# UM8 register map
Vendor: Redshift Labs Pty Ltd; Series: IMU; File version: 0.1
UM8 Board Peripheral Description
Address unit: 32 bits
Registers are 32-bit, read-only, reset 0x0 unless marked. A register's access mark holds for its fields unless they carry their own. Offsets are from the block's base; lines under a group give offsets from that group; [hi:lo] are bit positions; {n}, {i} and the like mark numbered series; 'fields as' and 'values as' point back to an identical list; <NAME> marks a mode.

## Memory map
0x00000000 MAIN_REGISTER_MAP size 0x500 — Main register map for the UM8 board
0x00000000 HIDDEN_REGISTER_MAP size 0x500 — Hidden register map for the UM8 board

## MAIN_REGISTER_MAP — Main register map for the UM8 board
Base 0x00000000
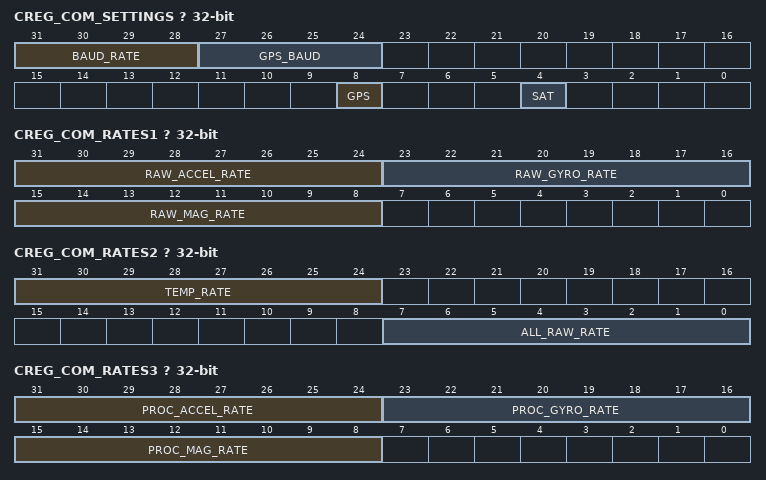
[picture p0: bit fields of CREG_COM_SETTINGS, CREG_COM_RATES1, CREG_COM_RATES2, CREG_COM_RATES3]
? CREG_COM_SETTINGS rw — The CREG_COM_SETTINGS register is used to set the boards serial port baud rate and to enable (disable) the automatic transmission of sensor data and estimated states (telemetry).
  [31:28] BAUD_RATE — Sets the baud rate of the boards main serial port:
    0=Baud rate: 9600; 1=Baud rate: 14400; 2=Baud rate: 19200; 3=Baud rate: 38400; 4=Baud rate: 57600; 5=Baud rate: 115200; 6=Baud rate: 128000; 7=Baud rate: 153600; 8=Baud rate: 230400; 9=Baud rate: 256000; 10=Baud rate: 460800; 11=Baud rate: 921600
  [27:24] GPS_BAUD — Sets the baud rate of the UM8 auxiliary serial port:
    0=Baud rate: 9600; 1=Baud rate: 14400; 2=Baud rate: 19200; 3=Baud rate: 38400; 4=Baud rate: 57600; 5=Baud rate: 115200
  [8] GPS — If set, this bit causes GPS data to be transmitted automatically whenever new GPS data is received. GPS data is stored in registers 125 to 130. These registers will be transmitted in a batch packet of length 6 starting at address 125.
    1=GPS_DATA_ON (GPS data will be transmitted automatically whenever new GPS data is received.); 0=GPS_DATA_OFF (GPS data will *not* be transmitted automatically whenever new GPS data is received.)
  [4] SAT — If set, this bit causes satellite details to be transmitted whenever they are provided by the GPS. Satellite information is stored in registers 131 to 136. These registers will be transmitted in a batch packet of length 6 beginning at address 131.
    1=SAT_DETAILS_ON (Satellite details will be transmitted whenever they are provided by the GPS.); 0=SAT_DETAILS_OFF (Satellite details will not be transmitted whenever they are provided by the GPS.)
? CREG_COM_RATES1 rw — The CREG_COM_RATES1 register sets desired telemetry transmission rates in Hz for raw accelerometer, gyro, and magnetometer data. If the specified rate is 0, then no data is transmitted.
  [31:24] RAW_ACCEL_RATE — Specifies the desired raw accelerometer data broadcast rate in Hz. The data is stored as an unsigned 8-bit integer, yielding a maximum rate of 255 Hz.
  [23:16] RAW_GYRO_RATE — Specifies the desired raw gyro data broadcast rate in Hz. The data is stored as an unsigned 8-bit integer, yielding a maximum rate of 255 Hz.
  [15:8] RAW_MAG_RATE — Specifies the desired raw magnetometer data broadcast rate in Hz. The data is stored as an unsigned 8-bit integer, yielding a maximum rate of 255 Hz.
? CREG_COM_RATES2 rw — The CREG_COM_RATES2 register sets desired telemetry transmission rates for all raw data and temperature. If the specified rate is 0, then no data is transmitted.
  [31:24] TEMP_RATE — Specifies the desired broadcast rate for temperature data. The data is stored as an unsigned 8-bit integer, yielding a maximum rate of 255 Hz.
  [7:0] ALL_RAW_RATE — Specifies the desired broadcast rate for all raw sensor data. If set, this overrides the broadcast rate setting for individual raw data broadcast rates. The data is stored as an unsigned 8-bit integer, yielding a maximum rate of 255 Hz.
? CREG_COM_RATES3 rw — The CREG_COM_RATES3 register sets desired telemetry transmission rates for processed sensor data. If the specified rate is 0, then no data is transmitted.
  [31:24] PROC_ACCEL_RATE — Specifies the desired broadcast rate for processed accelerometer data. The data is stored as an unsigned 8-bit integer, yielding a maximum rate of 255 Hz.
  [23:16] PROC_GYRO_RATE — Specifies the desired broadcast rate for processed rate gyro data. The data is stored as an unsigned 8-bit integer, yielding a maximum rate of 255 Hz.
  [15:8] PROC_MAG_RATE — Specifies the desired broadcast rate for processed magnetometer data. The data is stored as an unsigned 8-bit integer, yielding a maximum rate of 255 Hz.
? CREG_COM_RATES4 rw — The CREG_COM_RATES4 register defines the desired telemetry transmission rates for all processed data. If the specified rate is 0, then no data is transmitted.
  [7:0] ALL_PROC_RATE — Specifies the desired broadcast rate for raw all processed data. If set, this overrides the broadcast rate setting for individual processed data broadcast rates. The data is stored as an unsigned 8-bit integer, yielding a maximum rate of 255 Hz.
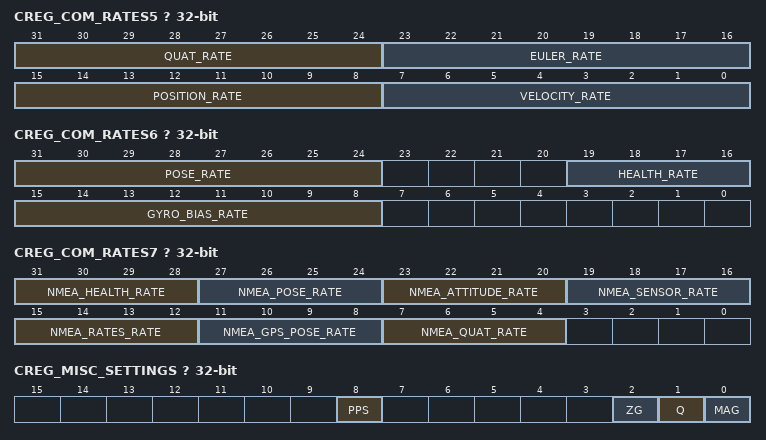
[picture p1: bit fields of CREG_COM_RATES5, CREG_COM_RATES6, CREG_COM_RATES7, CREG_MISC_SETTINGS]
? CREG_COM_RATES5 rw — The CREG_COM_RATES5 register sets desired telemetry transmission rates for quaternions, Euler Angles, position, and velocity estimates. If the specified rate is 0, then no data is transmitted.
  [31:24] QUAT_RATE — Specifies the desired broadcast rate for quaternion data. The data is stored as an unsigned 8-bit integer, yielding a maximum rate of 255 Hz.
  [23:16] EULER_RATE — Specifies the desired broadcast rate for Euler Angle data. The data is stored as an unsigned 8-bit integer, yielding a maximum rate of 255 Hz.
  [15:8] POSITION_RATE — Specifies the desired broadcast rate position. The data is stored as an unsigned 8-bit integer, yielding a maximum rate of 255 Hz.
  [7:0] VELOCITY_RATE — Specifies the desired broadcast rate for velocity. The data is stored as an unsigned 8-bit integer, yielding a maximum rate of 255 Hz.
? CREG_COM_RATES6 rw — The CREG_COM_RATES6 register sets desired telemetry transmission rates for pose (Euler/position packet), health, and gyro bias estimates for the gyro 1 and gyro 2. If the specified rate is 0, then no data is transmitted.
  [31:24] POSE_RATE — Specifies the desired broadcast rate for pose (Euler Angle and position) data. The data is stored as an unsigned 8-bit integer, yielding a maximum rate of 255 Hz.
  [19:16] HEALTH_RATE — Specifies the desired broadcast rate for the sensor health packet.
    0=Packet frequency: OFF; 1=0_125 (Packet frequency: 0.125 Hz); 2=0_25 (Packet frequency: 0.25 Hz); 3=0_5 (Packet frequency: 0.5 Hz); 4=Packet frequency: 1 Hz; 5=Packet frequency: 2 Hz; 6=Packet frequency: 4 Hz
  [15:8] GYRO_BIAS_RATE — Specifies the desired broadcast rate for gyro bias estimates. The data is stored as an unsigned 8-bit integer, yielding a maximum rate of 255 Hz.
? CREG_COM_RATES7 rw — The CREG_COM_RATES7 register sets desired telemetry transmission rates in Hz for NMEA packets.
  [all] fields
    0=Packet frequency: OFF; 1=Packet frequency: 1 Hz; 2=Packet frequency: 2 Hz; 3=Packet frequency: 4 Hz; 4=Packet frequency: 5 Hz; 5=Packet frequency: 10 Hz; 6=Packet frequency: 15 Hz; 7=Packet frequency: 20 Hz; 8=Packet frequency: 30 Hz; 9=Packet frequency: 40 Hz; 10=Packet frequency: 50 Hz; 11=Packet frequency: 60 Hz; 12=Packet frequency: 70 Hz; 13=Packet frequency: 80 Hz; 14=Packet frequency: 90 Hz; 15=Packet frequency: 100 Hz
  [31:28] NMEA_HEALTH_RATE — Specifies the desired broadcast rate for Redshift Labs Pty Ltd NMEA-style health packet.
  [27:24] NMEA_POSE_RATE — Specifies the desired broadcast rate for Redshift Labs Pty Ltd NMEA-style pose (Euler Angle/position) packet.
  [23:20] NMEA_ATTITUDE_RATE — Specifies the desired broadcast rate for Redshift Labs Pty Ltd NMEA-style attitude packet.
  [19:16] NMEA_SENSOR_RATE — Specifies the desired broadcast rate for Redshift Labs Pty Ltd NMEA-style sensor data packet.
  [15:12] NMEA_RATES_RATE — Specifies the desired broadcast rate for Redshift Labs Pty Ltd NMEA-style rate data packet.
  [11:8] NMEA_GPS_POSE_RATE — Specifies the desired broadcast rate for Redshift Labs Pty Ltd NMEA-style GPS pose packet.
  [7:4] NMEA_QUAT_RATE — Specifies the desired broadcast rate for Redshift Labs Pty Ltd NMEA-style quaternion packet.
? CREG_MISC_SETTINGS rw — This register contains miscellaneous filter and sensor control options.
  [8] PPS — If set, this bit causes the TX2 pin on the IO Expansion header to be used as the PPS input from an external GPS module. PPS pulses will then be used to synchronize the system clock to UTC time of day.
    0=PPS_OFF (TX2 not used as PPS input from GPS); 1=PPS_ON (TX2 used as PPS input from GPS)
  [2] ZG — If set, this bit causes the device to attempt to measure the rate gyro bias on startup. The sensor must be stationary on startup for this feature to work properly.
    0=ZG_OFF (NOT measure rate gyro bias on startup); 1=ZG_ON (Measure rate gyro bias on startup)
  [1] Q — If this bit is set, the sensor will run in quaternion mode instead of Euler Angle mode.
    0=EULER_MODE (The sensor will run in Euler Angle mode); 1=QUATERNION_MODE (The sensor will run in quaternion mode)
  [0] MAG — If set, the magnetometer will be used in state updates.
    0=MAG_NOT_IN_STATE (NOT use magnetometer in state update); 1=MAG_IN_STATE (Use magnetometer in state update)
? CREG_HOME_NORTH rw — This register sets the north home latitude in degrees, used to convert GPS coordinates to position in meters from home.
  [31:0] SET_HOME_NORTH — North Position (32-bit IEEE Floating Point Value)
? CREG_HOME_EAST rw — This register sets the east home longitude in degrees, used to convert GPS coordinates to position in meters from home.
  [31:0] SET_HOME_EAST — East Position (32-bit IEEE Floating Point Value)
? CREG_HOME_UP rw — This register sets the home altitude in meters. Used to convert GPS coordinates to position in meters from home.
  [31:0] SET_HOME_UP — Altitude Position (32-bit IEEE Floating Point Value)
? CREG_GYRO_TRIM_X rw — This register sets the x-axis rate gyro trim, which is used to add additional bias compensation for the rate gyros during calls to the ZERO_GYRO_BIAS command.
  [31:0] GYRO_TRIM_X — 32-bit IEEE Floating Point Value
? CREG_GYRO_TRIM_Y rw — This register sets the y-axis rate gyro trim, which is used to add additional bias compensation for the rate gyros during calls to the ZERO_GYRO_BIAS command.
  [31:0] GYRO_TRIM_Y — 32-bit IEEE Floating Point Value
? CREG_GYRO_TRIM_Z rw — This register sets the z-axis rate gyro trim, which is used to add additional bias compensation for the rate gyros during calls to the ZERO_GYRO_BIAS command.
  [31:0] GYRO_TRIM_Z — 32-bit IEEE Floating Point Value
? CREG_MAG_CAL{i}_1 rw (i=1..3) — Row {i}, Column 1 of magnetometer calibration matrix.
  [31:0] MAG_CAL{i}_1 — 32-bit IEEE Floating Point Value
? CREG_MAG_CAL{i}_2 rw (i=1..3) — Row {i}, Column 2 of magnetometer calibration matrix.
  [31:0] MAG_CAL{i}_2 — 32-bit IEEE Floating Point Value
? CREG_MAG_CAL{i}_3 rw (i=1..3) — Row {i}, Column 3 of magnetometer calibration matrix.
  [31:0] MAG_CAL{i}_3 — 32-bit IEEE Floating Point Value
? CREG_MAG_BIAS_X rw — This register stores a bias term for the magnetometer x-axis for hard-iron calibration. This term can be computed by performing magnetometer calibration with the Redshift labs Serial Interface.
  [31:0] MAG_BIAS_X — 32-bit IEEE Floating Point Value
? CREG_MAG_BIAS_Y rw — This register stores a bias term for the magnetometer y-axis for hard-iron calibration. This term can be computed by performing magnetometer calibration with the Redshift labs Serial Interface.
  [31:0] MAG_BIAS_Y — 32-bit IEEE Floating Point Value
? CREG_MAG_BIAS_Z rw — This register stores a bias term for the magnetometer z-axis for hard-iron calibration. This term can be computed by performing magnetometer calibration with the Redshift labs Serial Interface.
  [31:0] MAG_BIAS_Z — 32-bit IEEE Floating Point Value
? CREG_ACCEL_CAL{i}_1 rw (i=1..3) — Row {i}, Column 1 of accelerometer calibration matrix.
  [31:0] ACCEL_CAL{i}_1 — 32-bit IEEE Floating Point Value
? CREG_ACCEL_CAL{i}_2 rw (i=1..3) — Row {i}, Column 2 of accelerometer calibration matrix.
  [31:0] ACCEL_CAL{i}_2 — 32-bit IEEE Floating Point Value
? CREG_ACCEL_CAL{i}_3 rw (i=1..3) — Row {i}, Column 3 of accelerometer calibration matrix.
  [31:0] ACCEL_CAL{i}_3 — 32-bit IEEE Floating Point Value
? CREG_ACCEL_BIAS_X rw — This register stores a bias term for the accelerometer x-axis for bias calibration. This term can be computed by performing calibrate accelerometers command within the Redshift labs Serial Interface.
  [31:0] ACCEL_BIAS_X — 32-bit IEEE Floating Point Value
? CREG_ACCEL_BIAS_Y rw — This register stores a bias term for the accelerometer y-axis for bias calibration. This term can be computed by performing calibrate accelerometers command within the Redshift labs Serial Interface.
  [31:0] ACCEL_BIAS_Y — 32-bit IEEE Floating Point Value
? CREG_ACCEL_BIAS_Z rw — This register stores a bias term for the accelerometer z-axis for bias calibration. This term can be computed by performing calibrate accelerometers command within the Redshift labs Serial Interface.
  [31:0] ACCEL_BIAS_Z — 32-bit IEEE Floating Point Value
? CREG_GYRO_1_MEAS_RANGE rw — The CREG_GYRO_1_MEAS_RANGE register sets the desired measurement range for the gyro 1 sensor. If the rate is not set, then the default value of 2000 deg/s will be used as a measurement range.
  [4:0] MEAS_GYRO1 — Specifies the desired measurement range for the gyro 1 measurements.
    0=2000_dps (Measurement range: +- 2000 dps); 1=1000_dps (Measurement range: +- 1000 dps); 2=500_dps (Measurement range: +- 500 dps); 3=250_dps (Measurement range: +- 250 dps); 4=125_dps (Measurement range: +- 125 dps); 5=62_5_dps (Measurement range: +- 62.5 dps); 6=31_25_dps (Measurement range: +- 31.25 dps); 7=15_625_dps (Measurement range: +- 15.625 dps); 8=19_BIT_2000_dps (Measurement range: +- 19 bit 2000 dps)
? CREG_ACCEL_1_MEAS_RANGE rw — The CREG_ACCEL_1_MEAS_RANGE register sets the desired measurement range for the accelerometer 1. If the rate is not set, then the default value of the +-2 g will be used as a measurement range.
  [1:0] MEAS_ACC1 — Specifies the desired measurement range for the accelerometer 1 measurements.
    0=2_g (Measurement range: +- 2 g); 1=4_g (Measurement range: +- 4 g); 2=8_g (Measurement range: +- 8 g); 3=16_g (Measurement range: +- 16 g); 4=18_BIT_16_g (Measurement range: +- 18 bit 16 g)
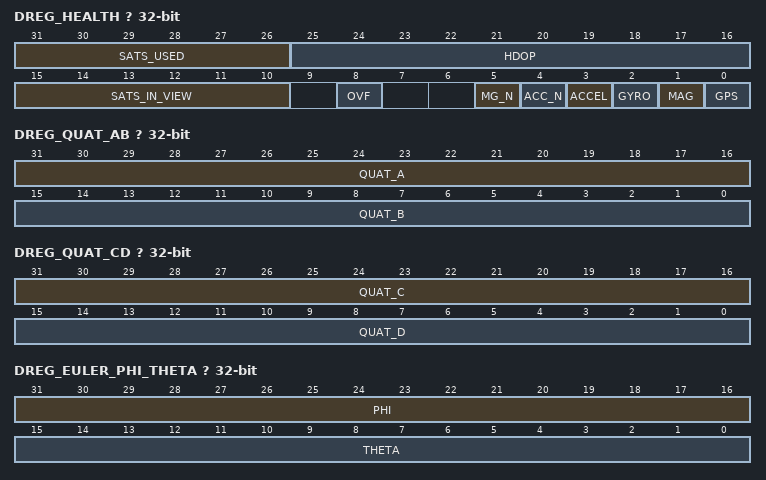
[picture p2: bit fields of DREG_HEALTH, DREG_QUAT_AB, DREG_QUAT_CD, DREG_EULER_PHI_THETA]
? DREG_HEALTH — The health register reports the current status of the GPS module and the other sensors on the board. Monitoring the health register is the easiest way to monitor the quality of the GPS lock and to watch for other problems that could affect the behavior of the board.
  [31:26] SATS_USED — Reports the number of satellites used in the position solution.
  [25:16] HDOP — Reports the horizontal dilution of precision (HDOP) reported by the GPS. The actual HDOP value is equal to the contents of the HDOP bits divided by 10.
  [15:10] SATS_IN_VIEW — Reports the number of satellites in view.
  [8] OVF — Overflow bit. This bit is set if the UM8 is attempting to transmit data over the serial port faster than is allowed given the baud-rate. If this bit is set, reduce broadcast rates in the COM_RATES registers.
    0=OVF_OFF (No overflow registered); 1=OVF_ON (Overflow registered, reduce broadcast rates)
  [5] MG_N — This bit is set if the sensor detects that the norm of the magnetometer measurement is too far away from 1.0 to be trusted. Usually indicates bad calibration, local field distortions, or both.
    0=MAG_NORM_OK (Magnetometer norm is OK); 1=MAG_NORM_WARN (Magnetometer norm is not OK)
  [4] ACC_N — This bit is set if the sensor detects that the norm of the accelerometer measurement is too far away from 1G to be used (i.e. during aggressive acceleration or high vibration).
    0=ACC_N_OFF (No high acceleration / no high vibration detected); 1=ACC_N_ON (High acceleration / high vibration detected)
  [3] ACCEL — This bit will be set if the accelerometer fails to initialize on startup.
    0=ACCEL_STARTUP_OK (Accelerometer startup OK); 1=ACCEL_STARTUP_ERR (Accelerometer startup error)
  [2] GYRO — This bit will be set if the rate gyro fails to initialize on startup.
    0=GYRO_STARTUP_OK; 1=GYRO_STARTUP_ERR (Gyro startup error)
  [1] MAG — This bit will be set if the magnetometer fails to initialize on startup.
    0=MAG_STARTUP_OK (Magnetometer startup OK); 1=MAG_STARTUP_ERR (Magnetometer startup error)
  [0] GPS — This bit is set if the GPS fails to send a packet for more than two seconds. If a GPS packet is ever received, this bit is cleared.
    0=GPS_GETTING_PACKETS (GPS packet was received within last 2 seconds); 1=GPS_NOT_GETTING_PACKETS (GPS packet was not received within last 2 seconds)
? DREG_GYRO_RAW_X — Contains raw X axis rate gyro data.
  [31:0] GYRO_RAW_X — Gyro X (2s complement 16-bit integer)
? DREG_GYRO_RAW_Y — Contains raw Y axis rate gyro data.
  [31:0] GYRO_RAW_Y — Gyro Y (2s complement 16-bit integer)
? DREG_GYRO_RAW_Z — Contains raw Z axis rate gyro data.
  [31:0] GYRO_RAW_Z — Gyro Z (2s complement 16-bit integer)
? DREG_GYRO_RAW_TIME — Contains time at which the last rate gyro data was acquired.
  [31:0] GYRO_RAW_TIME — 32-bit IEEE Floating Point Value
? DREG_ACCEL_RAW_X — Contains raw X axis accelerometer data.
  [31:0] ACCEL_RAW_X — Accel X (2s complement 16-bit integer)
? DREG_ACCEL_RAW_Y — Contains raw Y axis accelerometer data.
  [31:0] ACCEL_RAW_Y — Accel Y (2s complement 16-bit integer)
? DREG_ACCEL_RAW_Z — Contains raw Z axis accelerometer data.
  [31:0] ACCEL_RAW_Z — Accel Z (2s complement 16-bit integer)
? DREG_ACCEL_RAW_TIME — Contains time at which the last raw data sample for the accelerometer was acquired.
  [31:0] ACCEL_RAW_TIME — 32-bit IEEE Floating Point Value
? DREG_MAG_RAW_X — Contains raw X axis magnetometer data.
  [31:0] MAG_RAW_X — Magnetometer X (2s complement 16-bit integer)
? DREG_MAG_RAW_Y — Contains raw Y axis magnetometer data.
  [31:0] MAG_RAW_Y — Magnetometer Y (2s complement 16-bit integer)
? DREG_MAG_RAW_Z — Contains raw Z axis magnetometer data.
  [31:0] MAG_RAW_Z — Magnetometer Z (2s complement 16-bit integer)
? DREG_MAG_RAW_TIME — Contains time at which the last magnetometer data from the magnetometer was acquired.
  [31:0] MAG_RAW_TIME — 32-bit IEEE Floating Point Value
? DREG_TEMPERATURE — Contains the temperature output of the onboard temperature sensor.
  [31:0] TEMPERATURE — Temperature in degrees Celcius (32-bit IEEE Floating Point)
? DREG_TEMPERATURE_TIME — Contains time at which the last temperature was acquired.
  [31:0] TEMPERATURE_TIME — 32-bit IEEE Floating Point Value
? DREG_GYRO_PROC_X — Contains the actual measured angular rate from the gyro for the x axis in degrees/sec after calibration has been applied.
  [31:0] GYRO_PROC_X — Gyro X in degrees / sec (32-bit IEEE Floating Point Value)
? DREG_GYRO_PROC_Y — Contains the actual measured angular rate from the gyro for the y axis in degrees/sec after calibration has been applied.
  [31:0] GYRO_PROC_Y — Gyro Y in degrees / sec (32-bit IEEE Floating Point Value)
? DREG_GYRO_PROC_Z — Contains the actual measured angular rate from the gyro for the z axis in degrees/sec after calibration has been applied.
  [31:0] GYRO_PROC_Z — Gyro Z in degrees / sec (32-bit IEEE Floating Point Value)
? DREG_GYRO_PROC_TIME — Contains the time at which the last rate gyro data from the gyro was measured.
  [31:0] GYRO_PROC_TIME — Gyro time stamp (32-bit IEEE Floating Point Value)
? DREG_ACCEL_PROC_X — Contains the actual measured acceleration from the accelerometer for the x axis in m/s2 after calibration has been applied.
  [31:0] ACCEL_PROC_X — Acceleration X in m/s2 (32-bit IEEE Floating Point Value)
? DREG_ACCEL_PROC_Y — Contains the actual measured acceleration from the accelerometer for the y axis in m/s2 after calibration has been applied.
  [31:0] ACCEL_PROC_Y — Acceleration Y in m/s2 (32-bit IEEE Floating Point Value)
? DREG_ACCEL_PROC_Z — Contains the actual measured acceleration from the accelerometer for the z axis in m/s2 after calibration has been applied.
  [31:0] ACCEL_PROC_Z — Acceleration Z in m/s2 (32-bit IEEE Floating Point Value)
? DREG_ACCEL_PROC_TIME — Contains the time at which the last acceleration data from the accelerometer was measured.
  [31:0] ACCEL_PROC_TIME — Accelerometer time stamp (32-bit IEEE Floating Point Value)
? DREG_MAG_PROC_X — Contains the actual measured magnetic field from the magnetometer for the x axis after calibration has been applied.
  [31:0] MAG_PROC_X — Magnetometer X (32-bit IEEE Floating Point Value)
? DREG_MAG_PROC_Y — Contains the actual measured magnetic field from the magnetometer for the y axis after calibration has been applied.
  [31:0] MAG_PROC_Y — Magnetometer Y (32-bit IEEE Floating Point Value)
? DREG_MAG_PROC_Z — Contains the actual measured magnetic field from the magnetometer for the z axis after calibration has been applied.
  [31:0] MAG_PROC_Z — Magnetometer Z (32-bit IEEE Floating Point Value)
? DREG_MAG_PROC_TIME — Contains the time stamp at which the calibrated magnetometer data was acquired.
  [31:0] MAG_PROC_TIME — Magnetometer time stamp (32-bit IEEE Floating Point Value)
? DREG_QUAT_AB — Contains the first two components (a and b) of the estimated quaternion attitude.
  [31:16] QUAT_A — First quaternion component. Stored as a 16-bit signed integer. To get the actual value, divide by 29789.09091.
  [15:0] QUAT_B — Second quaternion component. Stored as a 16-bit signed integer. To get the actual value, divide by 29789.09091.
? DREG_QUAT_CD — Contains the second two components (c and d) of the estimated quaternion attitude.
  [31:16] QUAT_C — Third quaternion component. Stored as a 16-bit signed integer. To get the actual value, divide by 29789.09091.
  [15:0] QUAT_D — Fourth quaternion component. Stored as a 16-bit signed integer. To get the actual value, divide by 29789.09091.
? DREG_QUAT_TIME — Contains the time that the quaternion attitude was estimated.
  [31:0] QUAT_TIME — Quaternion time (32-bit IEEE Floating Point Value)
? DREG_EULER_PHI_THETA — Contains the pitch and roll angle estimates.
  [31:16] PHI — Roll angle. Stored as a 16-bit signed integer. To get the actual value, divide by 91.02222.
  [15:0] THETA — Pitch angle. Stored as a 16-bit signed integer. To get the actual value, divide by 91.02222.
? DREG_EULER_PSI — Contains the yaw angle estimate.
  [31:16] PSI — Yaw angle. Stored as a 16-bit signed integer. To get the actual value, divide by 91.02222.
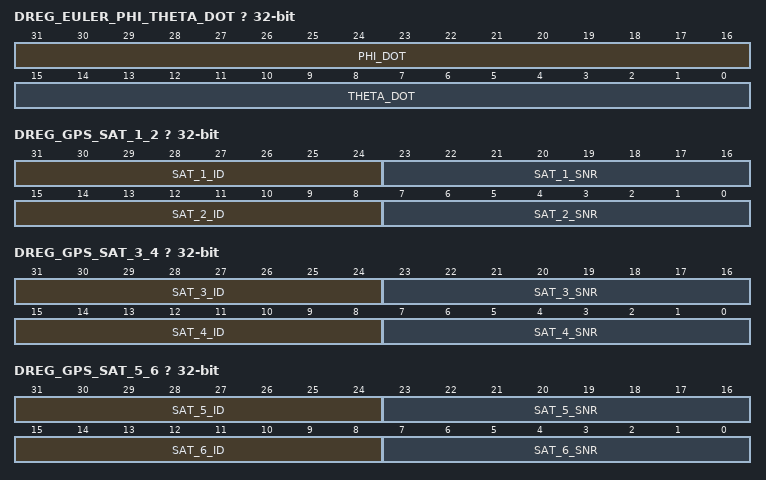
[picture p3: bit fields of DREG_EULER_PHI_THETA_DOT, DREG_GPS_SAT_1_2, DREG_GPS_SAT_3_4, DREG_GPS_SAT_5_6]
? DREG_EULER_PHI_THETA_DOT — Contains the pitch and roll rate estimates.
  [31:16] PHI_DOT — Roll rate. Stored as a 16-bit signed integer. To get the actual value, divide by 16.0.
  [15:0] THETA_DOT — Pitch rate. Stored as a 16-bit signed integer. To get the actual value, divide by 16.0.
? DREG_EULER_PSI_DOT — Contains the yaw rate estimate.
  [31:16] PSI_DOT — Yaw rate. Stored as a 16-bit signed integer. To get the actual value, divide by 16.0.
? DREG_EULER_TIME — Contains the time that the Euler Angles were estimated.
  [31:0] EULER_TIME — Euler time (32-bit IEEE Floating Point Value)
? DREG_POSITION_NORTH — Contains the measured north position in meters from the latitude specified in CREG_HOME_NORTH.
  [31:0] POSITION_NORTH — North Position (32-bit IEEE Floating Point Value)
? DREG_POSITION_EAST — Contains the measured east position in meters from the longitude specified in CREG_HOME_EAST.
  [31:0] POSITION_EAST — East Position (32-bit IEEE Floating Point Value)
? DREG_POSITION_UP — Contains the measured altitude in meters from the altitude specified in CREG_HOME_UP.
  [31:0] POSITION_UP — Altitude (32-bit IEEE Floating Point Value)
? DREG_POSITION_TIME — Contains the time at which the position was acquired.
  [31:0] POSITION_TIME — Position Time (32-bit IEEE Floating Point Value)
? DREG_VELOCITY_NORTH — Contains the measured north velocity in m/s.
  [31:0] VELOCITY_NORTH — North Velocity (32-bit IEEE Floating Point Value)
? DREG_VELOCITY_EAST — Contains the measured east velocity in m/s.
  [31:0] VELOCITY_EAST — East Velocity (32-bit IEEE Floating Point Value)
? DREG_VELOCITY_UP — Contains the measured altitude velocity in m/s.
  [31:0] VELOCITY_UP — Altitude Velocity (32-bit IEEE Floating Point Value)
? DREG_VELOCITY_TIME — Contains the time at which the velocity was measured.
  [31:0] VELOCITY_TIME — Velocity time (32-bit IEEE Floating Point Value)
? DREG_GPS_LATITUDE — Contains the GPS-reported latitude in degrees.
  [31:0] GPS_LATITUDE — GPS Latitude (32-bit IEEE Floating Point Value)
? DREG_GPS_LONGITUDE — Contains the GPS-reported longitude in degrees.
  [31:0] GPS_LONGITUDE — GPS Longitude (32-bit IEEE Floating Point Value)
? DREG_GPS_ALTITUDE — Contains the GPS-reported altitude in meters.
  [31:0] GPS_ALTITUDE — GPS Altitude (32-bit IEEE Floating Point Value)
? DREG_GPS_COURSE — Contains the GPS-reported course in degrees.
  [31:0] GPS_COURSE — GPS Course (32-bit IEEE Floating Point Value)
? DREG_GPS_SPEED — Contains the GPS-reported speed in m/s.
  [31:0] GPS_SPEED — GPS Speed (32-bit IEEE Floating Point Value)
? DREG_GPS_TIME — Contains the GPS-reported time in seconds from the last epoch.
  [31:0] GPS_TIME — GPS Speed (32-bit IEEE Floating Point Value)
? DREG_GPS_SAT_1_2 — Contains satellite ID and signal-to-noise ratio (SNR) for satellites 1 and 2.
  [31:24] SAT_1_ID — Satellite 1 ID
  [23:16] SAT_1_SNR — Signal-to-Noise Ratio of satellite 1 as reported by GPS receiver.
  [15:8] SAT_2_ID — Satellite 2 ID
  [7:0] SAT_2_SNR — Signal-to-Noise Ratio of satellite 2 as reported by GPS receiver.
? DREG_GPS_SAT_3_4 — Contains satellite ID and signal-to-noise ratio (SNR) for satellites 3 and 4.
  [31:24] SAT_3_ID — Satellite 3 ID
  [23:16] SAT_3_SNR — Signal-to-Noise Ratio of satellite 3 as reported by GPS receiver.
  [15:8] SAT_4_ID — Satellite 4 ID
  [7:0] SAT_4_SNR — Signal-to-Noise Ratio of satellite 4 as reported by GPS receiver.
? DREG_GPS_SAT_5_6 — Contains satellite ID and signal-to-noise ratio (SNR) for satellites 5 and 6.
  [31:24] SAT_5_ID — Satellite 5 ID
  [23:16] SAT_5_SNR — Signal-to-Noise Ratio of satellite 5 as reported by GPS receiver.
  [15:8] SAT_6_ID — Satellite 6 ID
  [7:0] SAT_6_SNR — Signal-to-Noise Ratio of satellite 6 as reported by GPS receiver.
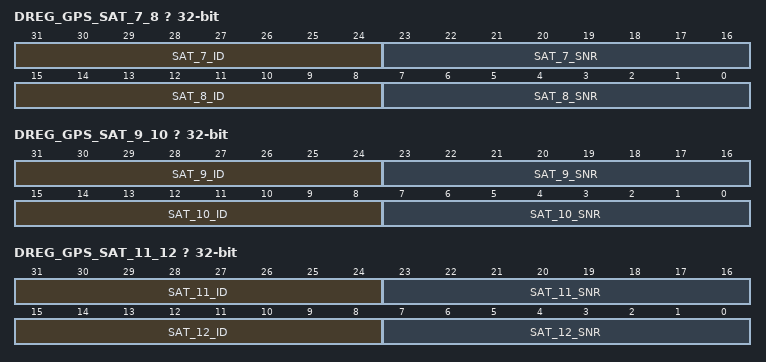
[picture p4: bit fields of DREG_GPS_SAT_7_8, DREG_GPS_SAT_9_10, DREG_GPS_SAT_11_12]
? DREG_GPS_SAT_7_8 — Contains satellite ID and signal-to-noise ratio (SNR) for satellites 7 and 8.
  [31:24] SAT_7_ID — Satellite 7 ID
  [23:16] SAT_7_SNR — Signal-to-Noise Ratio of satellite 7 as reported by GPS receiver.
  [15:8] SAT_8_ID — Satellite 8 ID
  [7:0] SAT_8_SNR — Signal-to-Noise Ratio of satellite 8 as reported by GPS receiver.
? DREG_GPS_SAT_9_10 — Contains satellite ID and signal-to-noise ratio (SNR) for satellites 9 and 10.
  [31:24] SAT_9_ID — Satellite 9 ID
  [23:16] SAT_9_SNR — Signal-to-Noise Ratio of satellite 9 as reported by GPS receiver.
  [15:8] SAT_10_ID — Satellite 10 ID
  [7:0] SAT_10_SNR — Signal-to-Noise Ratio of satellite 10 as reported by GPS receiver.
? DREG_GPS_SAT_11_12 — Contains satellite ID and signal-to-noise ratio (SNR) for satellites 11 and 12.
  [31:24] SAT_11_ID — Satellite 11 ID
  [23:16] SAT_11_SNR — Signal-to-Noise Ratio of satellite 11 as reported by GPS receiver.
  [15:8] SAT_12_ID — Satellite 12 ID
  [7:0] SAT_12_SNR — Signal-to-Noise Ratio of satellite 12 as reported by GPS receiver.
? DREG_GYRO_BIAS_X — Contains the estimated x-axis bias for the gyro in degrees/s.
  [31:0] GYRO_BIAS_X — Gyro bias X (32-bit IEEE Floating Point Value)
? DREG_GYRO_BIAS_Y — Contains the estimated y-axis bias for the gyro in degrees/s.
  [31:0] GYRO_BIAS_Y — Gyro bias Y (32-bit IEEE Floating Point Value)
? DREG_GYRO_BIAS_Z — Contains the estimated z-axis bias for the gyro in degrees/s.
  [31:0] GYRO_BIAS_Z — Gyro bias Z (32-bit IEEE Floating Point Value)
? DREG_MAG_1_NORM — Contains the L2-norm (magnetic norm) for the measured magnetic field from the magnetometer 1 computed over the calibrated values.
  [31:0] MAG_1_NORM — Magnetic norm (32-bit IEEE Floating Point Value)
? GET_FW_REVISION — Firmware build identification string: a four byte ASCII character sequence which corresponds to a firmware series.
  [31:0] FW_REVISION — Firmware revision string
? FLASH_COMMIT wo — Causes the board to write all configuration settings to FLASH so that are stored in the non-volatile memory and remain when the power is cycled.
  [0] FLASH_COMMIT ro — Command to write configuration settings to flash
? RESET_TO_FACTORY wo — Causes the board to load default factory settings.
  [0] RESET_TO_FACTORY_BIT
? ZERO_GYROS wo — Causes the board to measure the gyro outputs and set the output trim registers to compensate for any non-zero bias. The board should be kept stationary while the zero operation is underway.
  [0] ZERO_GYROS_BIT
? SET_HOME_POSITION wo — Sets the current GPS latitude, longitude, and altitude as the home position. All future positions will be referenced to the current GPS position.
  [0] SET_HOME_POSITION_BIT
? SET_MAG_REFERENCE wo — Sets the current yaw heading position as north.
  [0] SET_MAG_REFERENCE_BIT — Set magnetometer reference bit
? CALIBRATE_ACCELEROMETERS wo — Reboots the board and performs a crude calibration on the accelerometers. Best performed on a flat surface.
  [0] CALIBRATE_ACCELEROMETERS_BIT
? RESET_EKF wo — Resets the EKF sensor fusion algorithm.
  [0] RESET_EKF_BIT

## HIDDEN_REGISTER_MAP — Hidden register map for the UM8 board
Base 0x00000000
? HIDDEN_GYRO_VARIANCE rw — Gyro variance
  [31:0] GYRO_VARIANCE — Gyro variance for EKF
? HIDDEN_ACCEL_VARIANCE rw — Accelerometer variance
  [31:0] ACCEL_VARIANCE — Accelerometer variance IEEE floating point value.

## Licence text in the file
Redshift Labs Pty Ltd modified this file. ARM Limited (ARM) is supplying this software for use with Cortex-M processor based microcontroller, but can be equally used for other suitable processor architectures. This file can be freely distributed. Modifications to this file shall be clearly marked. . THIS SOFTWARE IS PROVIDED "AS IS". NO WARRANTIES, WHETHER EXPRESS, IMPLIED. OR STATUTORY, INCLUDING, BUT NOT LIMITED TO, IMPLIED WARRANTIES OF. MERCHANTABILITY AND FITNESS FOR A PARTICULAR PURPOSE APPLY TO THIS SOFTWARE. ARM SHALL NOT, IN ANY CIRCUMSTANCES, BE LIABLE FOR SPECIAL, INCIDENTAL, OR. CONSEQUENTIAL DAMAGES, FOR ANY REASON WHATSOEVER.

## Notices in the file
Copyright (C) 2012-2014 ARM Limited. All rights reserved.
Redistribution and use in source and binary forms, with or without
modification, are permitted provided that the following conditions are met:
- Redistributions of source code must retain the above copyright
notice, this list of conditions and the following disclaimer.
- Redistributions in binary form must reproduce the above copyright
notice, this list of conditions and the following disclaimer in the
documentation and/or other materials provided with the distribution.
- Neither the name of ARM nor the names of its contributors may be used
to endorse or promote products derived from this software without
specific prior written permission.
THIS SOFTWARE IS PROVIDED BY THE COPYRIGHT HOLDERS AND CONTRIBUTORS "AS IS"
AND ANY EXPRESS OR IMPLIED WARRANTIES, INCLUDING, BUT NOT LIMITED TO, THE
ARE DISCLAIMED. IN NO EVENT SHALL COPYRIGHT HOLDERS AND CONTRIBUTORS BE
LIABLE FOR ANY DIRECT, INDIRECT, INCIDENTAL, SPECIAL, EXEMPLARY, OR
CONSEQUENTIAL DAMAGES (INCLUDING, BUT NOT LIMITED TO, PROCUREMENT OF
SUBSTITUTE GOODS OR SERVICES; LOSS OF USE, DATA, OR PROFITS; OR BUSINESS
INTERRUPTION) HOWEVER CAUSED AND ON ANY THEORY OF LIABILITY, WHETHER IN
CONTRACT, STRICT LIABILITY, OR TORT (INCLUDING NEGLIGENCE OR OTHERWISE)
ARISING IN ANY WAY OUT OF THE USE OF THIS SOFTWARE, EVEN IF ADVISED OF THE
POSSIBILITY OF SUCH DAMAGE.
